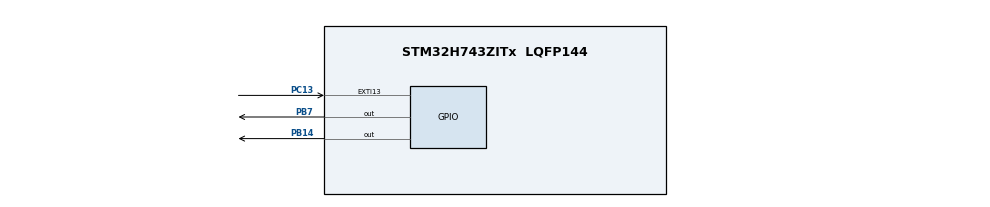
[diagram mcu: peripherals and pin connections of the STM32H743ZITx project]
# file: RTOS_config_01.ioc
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Mcu.Family=STM32H7
RCC.CortexFreq_Value=480000000
PA13\ (JTMS/SWDIO).Mode=Serial_Wire
RCC.HPRE=RCC_HCLK_DIV2
PC13.Signal=GPXTI13
RCC.PLLFRACN=0
RCC.D2PPRE2=RCC_APB2_DIV2
RCC.D2PPRE1=RCC_APB1_DIV2
RCC.PLL2FRACN=0
RCC.SYSCLKSource=RCC_SYSCLKSOURCE_PLLCLK
ProjectManager.StackSize=0x400
PA14\ (JTCK/SWCLK).Signal=DEBUG_JTCK-SWCLK
ProjectManager.TargetToolchain=STM32CubeIDE
RCC.HCLKFreq_Value=240000000
RCC.DIVN1=60
RCC.USBFreq_Value=480000000
PB14.Signal=GPIO_Output
board=custom
RCC.DIVM1=4
RCC.APB2Freq_Value=120000000
RCC.ADCFreq_Value=129000000
PB7.Signal=GPIO_Output
PA14\ (JTCK/SWCLK).Mode=Serial_Wire
Mcu.Name=STM32H743ZITx
RCC.APB3Freq_Value=120000000
RCC.SYSCLKFreq_VALUE=480000000
Mcu.Package=LQFP144
RCC.PLL3FRACN=0
RCC.D1PPRE=RCC_APB3_DIV2
ProjectManager.HeapSize=0x200
NVIC.PriorityGroup=NVIC_PRIORITYGROUP_4
RCC.APB4Freq_Value=120000000
RCC.D3PPRE=RCC_APB4_DIV2
RCC.APB1Freq_Value=120000000
PA13\ (JTMS/SWDIO).Signal=DEBUG_JTMS-SWDIO

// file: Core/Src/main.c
/* USER CODE BEGIN Header */
/**
  ******************************************************************************
  * @file           : main.c
  * @brief          : Main program body
  ******************************************************************************
  * @attention
  *
  * <h2><center>&copy; Copyright (c) 2021 STMicroelectronics.
  * All rights reserved.</center></h2>
  *
  * This software component is licensed by ST under BSD 3-Clause license,
  * the "License"; You may not use this file except in compliance with the
  * License. You may obtain a copy of the License at:
  *                        opensource.org/licenses/BSD-3-Clause
  *
  ******************************************************************************
  */
/* USER CODE END Header */
#include "main.h"

void SystemClock_Config(void);
static void MX_GPIO_Init(void);
/* USER CODE BEGIN PFP */
//static void HW_init(void);
static void Kernel_init(void);
/* USER CODE END PFP */

/* USER CODE BEGIN 0 */
void User_task0(void);
void User_task1(void);
void User_task2(void);
/* USER CODE END 0 */

int main(void)
{

  /* MCU Configuration--------------------------------------------------------*/

  /* Reset of all peripherals, Initializes the Flash interface and the Systick. */
  HAL_Init();

  /* USER CODE BEGIN Init */
  HW_init();
  /* USER CODE END Init */

  /* Configure the system clock */
  SystemClock_Config();

  /* Initialize all configured peripherals */
  MX_GPIO_Init();

  /* Infinite loop */
  while (1)
  {

  }
}

void SystemClock_Config(void)
{
  RCC_OscInitTypeDef RCC_OscInitStruct = {0};
  RCC_ClkInitTypeDef RCC_ClkInitStruct = {0};

  /** Supply configuration update enable
  */
  HAL_PWREx_ConfigSupply(PWR_LDO_SUPPLY);
  /** Configure the main internal regulator output voltage
  */
  __HAL_PWR_VOLTAGESCALING_CONFIG(PWR_REGULATOR_VOLTAGE_SCALE0);

  while(!__HAL_PWR_GET_FLAG(PWR_FLAG_VOSRDY)) {}
  /** Initializes the RCC Oscillators according to the specified parameters
  * in the RCC_OscInitTypeDef structure.
  */
  RCC_OscInitStruct.OscillatorType = RCC_OSCILLATORTYPE_HSI;
  RCC_OscInitStruct.HSIState = RCC_HSI_DIV1;
  RCC_OscInitStruct.HSICalibrationValue = RCC_HSICALIBRATION_DEFAULT;
  RCC_OscInitStruct.PLL.PLLState = RCC_PLL_ON;
  RCC_OscInitStruct.PLL.PLLSource = RCC_PLLSOURCE_HSI;
  RCC_OscInitStruct.PLL.PLLM = 4;
  RCC_OscInitStruct.PLL.PLLN = 60;
  RCC_OscInitStruct.PLL.PLLP = 2;
  RCC_OscInitStruct.PLL.PLLQ = 2;
  RCC_OscInitStruct.PLL.PLLR = 2;
  RCC_OscInitStruct.PLL.PLLRGE = RCC_PLL1VCIRANGE_3;
  RCC_OscInitStruct.PLL.PLLVCOSEL = RCC_PLL1VCOWIDE;
  RCC_OscInitStruct.PLL.PLLFRACN = 0;
  if (HAL_RCC_OscConfig(&RCC_OscInitStruct) != HAL_OK)
  {
    Error_Handler();
  }
  /** Initializes the CPU, AHB and APB buses clocks
  */
  RCC_ClkInitStruct.ClockType = RCC_CLOCKTYPE_HCLK|RCC_CLOCKTYPE_SYSCLK
                              |RCC_CLOCKTYPE_PCLK1|RCC_CLOCKTYPE_PCLK2
                              |RCC_CLOCKTYPE_D3PCLK1|RCC_CLOCKTYPE_D1PCLK1;
  RCC_ClkInitStruct.SYSCLKSource = RCC_SYSCLKSOURCE_PLLCLK;
  RCC_ClkInitStruct.SYSCLKDivider = RCC_SYSCLK_DIV1;
  RCC_ClkInitStruct.AHBCLKDivider = RCC_HCLK_DIV2;
  RCC_ClkInitStruct.APB3CLKDivider = RCC_APB3_DIV2;
  RCC_ClkInitStruct.APB1CLKDivider = RCC_APB1_DIV2;
  RCC_ClkInitStruct.APB2CLKDivider = RCC_APB2_DIV2;
  RCC_ClkInitStruct.APB4CLKDivider = RCC_APB4_DIV2;

  if (HAL_RCC_ClockConfig(&RCC_ClkInitStruct, FLASH_LATENCY_4) != HAL_OK)
  {
    Error_Handler();
  }
}

static void MX_GPIO_Init(void)
{
  GPIO_InitTypeDef GPIO_InitStruct = {0};

  /* GPIO Ports Clock Enable */
  __HAL_RCC_GPIOC_CLK_ENABLE();
  __HAL_RCC_GPIOB_CLK_ENABLE();
  __HAL_RCC_GPIOA_CLK_ENABLE();

  /*Configure GPIO pin Output Level */
  HAL_GPIO_WritePin(GPIOB, GPIO_PIN_14|GPIO_PIN_7, GPIO_PIN_RESET);

  /*Configure GPIO pin : PC13 */ //User button
  GPIO_InitStruct.Pin = GPIO_PIN_13;
  GPIO_InitStruct.Mode = GPIO_MODE_IT_RISING;
  GPIO_InitStruct.Pull = GPIO_NOPULL;
  HAL_GPIO_Init(GPIOC, &GPIO_InitStruct);

  /*Configure GPIO pins : PB14 PB7 */
  GPIO_InitStruct.Pin = GPIO_PIN_14|GPIO_PIN_7;
  GPIO_InitStruct.Mode = GPIO_MODE_OUTPUT_PP;
  GPIO_InitStruct.Pull = GPIO_NOPULL;
  GPIO_InitStruct.Speed = GPIO_SPEED_FREQ_LOW;
  HAL_GPIO_Init(GPIOB, &GPIO_InitStruct);

}

/* USER CODE BEGIN 4 */
static void Kernel_init(void)
{
    uint32_t taskID;

    Kernel_task_init();

    taskID = Kernel_task_create(User_task0);
    if(NOT_ENOUGH_TASK_NUM == taskID)
    {
        putstr("Task0 creation failed\n");
    }

    taskID = Kernel_task_create(User_task1);
    if(NOT_ENOUGH_TASK_NUM == taskID)
    {
        putstr("Task1 creation failed\n");
    }

    taskID = Kernel_task_create(User_task2);
    if(NOT_ENOUGH_TASK_NUM == taskID)
    {
        putstr("Task2 creation failed\n");
    }
}

/* USER CODE END 4 */

void Error_Handler(void)
{
  __disable_irq();
  while (1)
  {
  }
}

/************************ (C) COPYRIGHT STMicroelectronics *****END OF FILE****/
